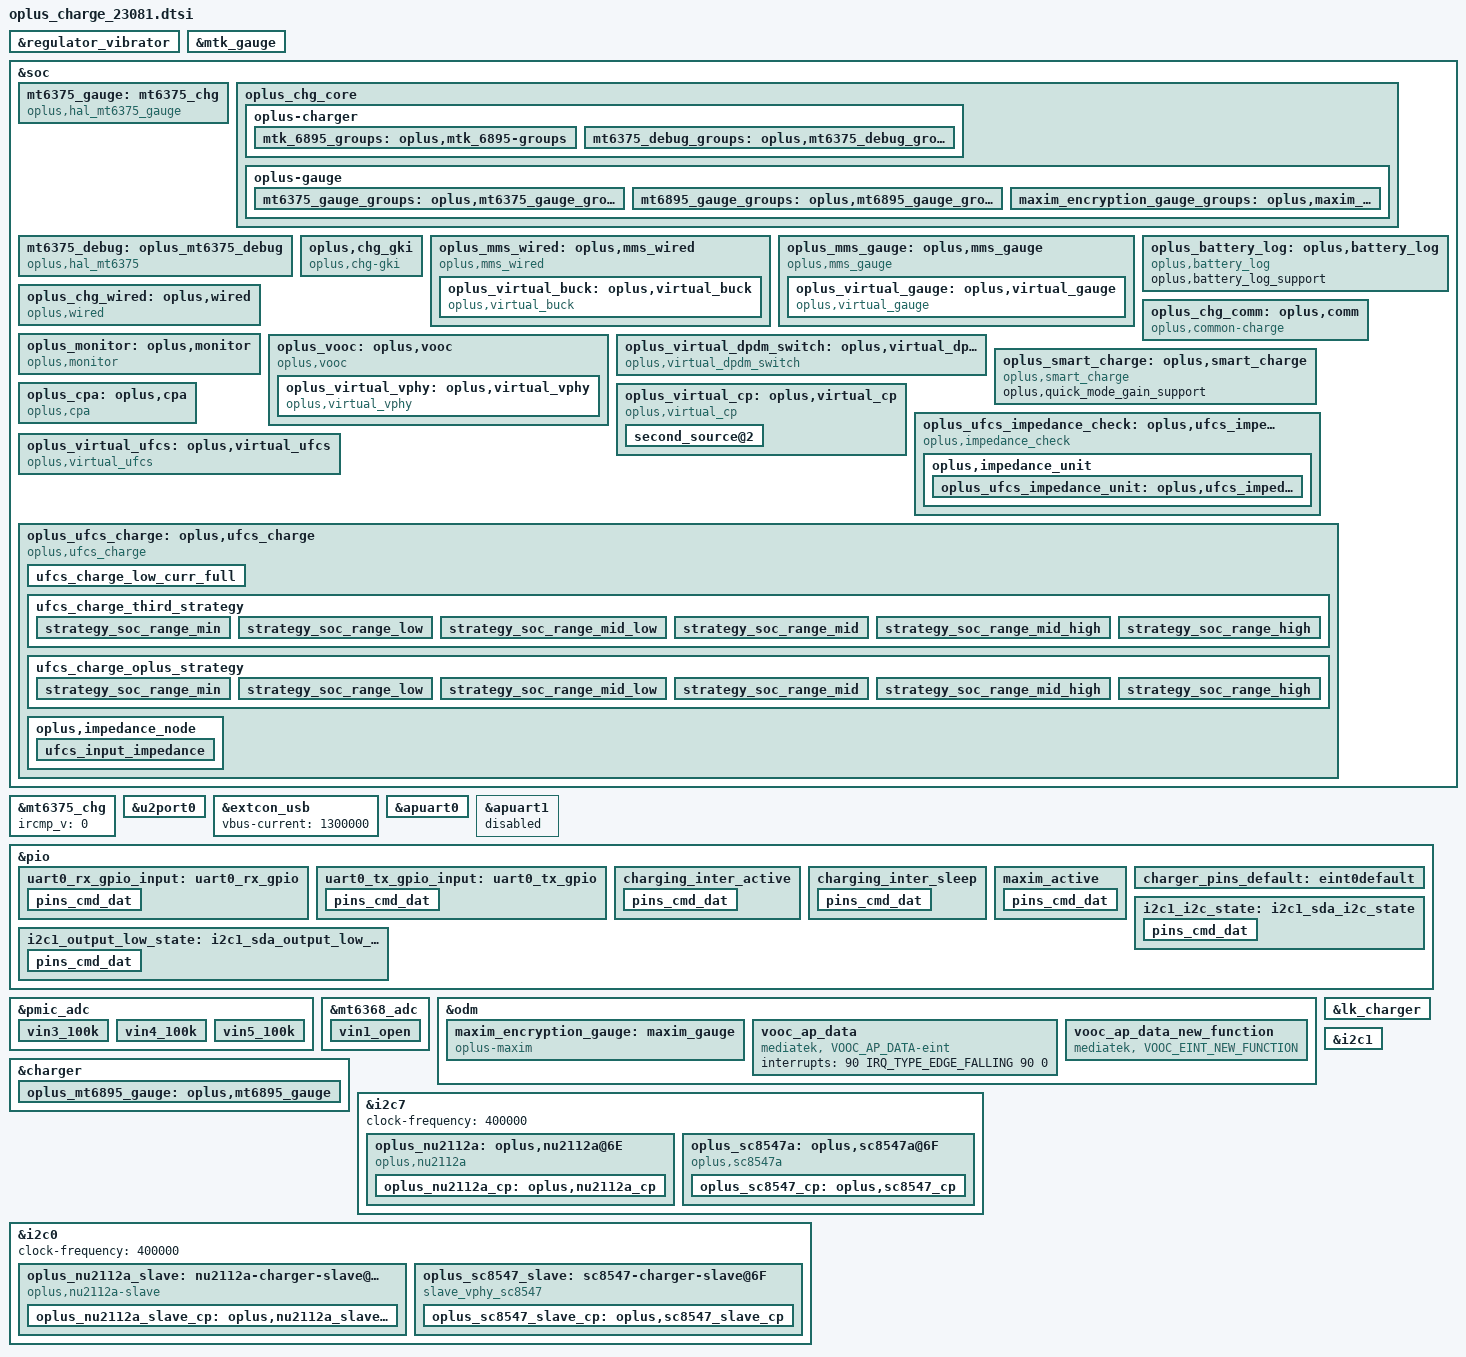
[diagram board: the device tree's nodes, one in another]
// SPDX-License-Identifier: GPL-2.0-only
/*
* Copyright (C) 2021-2020 Oplus. All rights reserved.
*/
#include <dt-bindings/iio/mt635x-auxadc.h>
#include <dt-bindings/pinctrl/mt6373-pinfunc.h>
#include <dt-bindings/pinctrl/mt65xx.h>
#include "oplus_chg.h"

/*
* ship mode gpio 119
* uart rx gpio88
* uart tx gpio89
* ntc adc need modify
*/

/* charge start */
&regulator_vibrator{
	min-volt = <3000000>;
	max-volt = <3000000>;
};

&mtk_gauge {
	status = "okay";
	charger = <&mt6375_chg>;
	FUELGAGUE_APPLY = <(1)>;
	IS_SUBBOARD_TEMP_SUPPORT = <(0)>;
	Enable_Is_Force_Full = <(1)>;
	RBAT_PULL_DOWN_R = <(24000)>;
	RBAT_PULL_UP_R = <(12000)>;
	USE_MORE_PRECISE_NTC_TABLE = <(1)>;
	R_FG_VALUE = <(1)>;
	CAR_TUNE_VALUE = <(109)>;
	AGING_FACTOR_MIN = <(93)>;
	AGING_FACTOR_DIFF = <(1)>;
	#include "mediatek/bat_setting/mt6895_23081_battery_table_ext.dtsi"
	#include "mediatek/bat_setting/mt6895_23081_battery_prop_dim2_ext.dtsi"
};

&soc {
	mt6375_gauge: mt6375_chg {
		status = "okay";
		compatible = "oplus,hal_mt6375_gauge";

		oplus,ic_type = <OPLUS_CHG_IC_GAUGE>;
		oplus,ic_index = <0>;
		oplus,batt_num = <1>;
		oplus,mtk_gauge_power_sel_support;
	};
};

&mt6375_chg {
	ircmp_v = <0>;
};

&u2port0 {
	mediatek,eye-vrt = <7>;
	mediatek,eye-term = <7>;
	mediatek,rev6 = <3>;
	mediatek,eye-vrt-host = <3>;
	mediatek,eye-term-host = <2>;
	mediatek,rev6-host = <3>;
	mediatek,discth = <0xd>;
};

&extcon_usb {
	vbus-current = <1300000>;
};

&apuart0 {
	pinctrl-names = "uart0_rx_gpio", "uart0_tx_gpio";
	pinctrl-0 = <&uart0_rx_gpio_input>;
	pinctrl-1 = <&uart0_tx_gpio_input>;
	status = "okay";
};

&apuart1 {
	status = "disabled";
};

&pio {
	uart0_rx_gpio_input: uart0_rx_gpio {
		pins_cmd_dat {
			pinmux = <PINMUX_GPIO88__FUNC_GPIO88>; /* URXD0 */
			input-enable;
			bias-disable;
		};
	};

	uart0_tx_gpio_input: uart0_tx_gpio {
		pins_cmd_dat {
			pinmux = <PINMUX_GPIO89__FUNC_GPIO89>; /* UTXD0 */
			input-enable;
			bias-disable;
		};
	};
};

&pmic_adc {
	vin3_100k {
		channel = <AUXADC_VIN3>;
		pures = <ADC_PURES_100K>;
	};
	vin4_100k {
		channel = <AUXADC_VIN4>;
		pures = <ADC_PURES_100K>;
	};
	vin5_100k {
		channel = <AUXADC_VIN5>;
		pures = <ADC_PURES_100K>;
	};
};

&mt6368_adc {
        vin1_open {
                channel = <AUXADC_VIN1>;
                pures = <ADC_PURES_OPEN>;
        };
};

&pio {
	charging_inter_active: charging_inter_active {
		pins_cmd_dat {
			pinmux = <PINMUX_GPIO10__FUNC_GPIO10>;
			input-enable;
			bias-pull-up;
			slew-rate = <0>;
		};
	};
	charging_inter_sleep: charging_inter_sleep {
		pins_cmd_dat {
			pinmux = <PINMUX_GPIO10__FUNC_GPIO10>;
			slew-rate = <0>;
		};
	};
};

&soc {
	oplus_chg_core {
		oplus,chg_framework_v2;
		oplus,smart_charging_screenoff;

		oplus-charger {
			mtk_6895_groups: oplus,mtk_6895-groups {
				functions = <
					OPLUS_IC_FUNC_INIT
					OPLUS_IC_FUNC_EXIT
					OPLUS_IC_FUNC_REG_DUMP
					OPLUS_IC_FUNC_SMT_TEST
					OPLUS_IC_FUNC_BUCK_INPUT_PRESENT
					OPLUS_IC_FUNC_BUCK_INPUT_SUSPEND
					OPLUS_IC_FUNC_BUCK_INPUT_IS_SUSPEND
					OPLUS_IC_FUNC_BUCK_OUTPUT_SUSPEND
					OPLUS_IC_FUNC_BUCK_OUTPUT_IS_SUSPEND
					OPLUS_IC_FUNC_BUCK_SET_ICL
					OPLUS_IC_FUNC_BUCK_GET_ICL
					OPLUS_IC_FUNC_BUCK_SET_FCC
					OPLUS_IC_FUNC_BUCK_SET_FV
					OPLUS_IC_FUNC_BUCK_SET_ITERM
					OPLUS_IC_FUNC_BUCK_GET_INPUT_CURR
					OPLUS_IC_FUNC_BUCK_GET_INPUT_VOL
					OPLUS_IC_FUNC_OTG_BOOST_ENABLE
					OPLUS_IC_FUNC_BUCK_GET_CC_ORIENTATION
					OPLUS_IC_FUNC_BUCK_GET_CHARGER_TYPE
					OPLUS_IC_FUNC_BUCK_RERUN_BC12
					OPLUS_IC_FUNC_BUCK_QC_DETECT_ENABLE
					OPLUS_IC_FUNC_BUCK_SET_QC_CONFIG
					OPLUS_IC_FUNC_BUCK_SET_PD_CONFIG
					OPLUS_IC_FUNC_GET_SHUTDOWN_SOC
					OPLUS_IC_FUNC_BACKUP_SOC
					OPLUS_IC_FUNC_GET_TYPEC_MODE
					OPLUS_IC_FUNC_SET_TYPEC_MODE
					OPLUS_IC_FUNC_GET_OTG_ENABLE
					OPLUS_IC_FUNC_BUCK_GET_HW_DETECT
					OPLUS_IC_FUNC_SET_USB_DISCHG_ENABLE
					OPLUS_IC_FUNC_GET_USB_DISCHG_STATUS
					OPLUS_IC_FUNC_IS_OPLUS_SVID
					OPLUS_IC_FUNC_BUCK_GET_TYPEC_STATE
					OPLUS_IC_FUNC_BUCK_GET_USB_BTB_TEMP
					OPLUS_IC_FUNC_BUCK_GET_BATT_BTB_TEMP
					OPLUS_IC_FUNC_BUCK_SHIPMODE_ENABLE
					OPLUS_IC_FUNC_BUCK_SET_AICL_POINT
					OPLUS_IC_FUNC_SET_OTG_BOOST_CURR_LIMIT
					OPLUS_IC_FUNC_GET_TYPEC_ROLE
				>;
				virqs = <
					OPLUS_IC_VIRQ_ERR
					OPLUS_IC_VIRQ_CC_DETECT
					OPLUS_IC_VIRQ_PLUGIN
					OPLUS_IC_VIRQ_CC_CHANGED
					OPLUS_IC_VIRQ_CHG_TYPE_CHANGE
					OPLUS_IC_VIRQ_OTG_ENABLE
					OPLUS_IC_VIRQ_SVID
					OPLUS_IC_VIRQ_TYPEC_STATE
				>;
			};

			mt6375_debug_groups: oplus,mt6375_debug_groups {
				functions = <
					OPLUS_IC_FUNC_INIT
					OPLUS_IC_FUNC_EXIT
				>;
				virqs = <
					OPLUS_IC_VIRQ_ERR
				>;
			};
		};

		oplus-gauge {
			mt6375_gauge_groups: oplus,mt6375_gauge_groups {
				functions = <
					OPLUS_IC_FUNC_INIT
					OPLUS_IC_FUNC_EXIT
					OPLUS_IC_FUNC_REG_DUMP
					OPLUS_IC_FUNC_SMT_TEST
					OPLUS_IC_FUNC_GAUGE_GET_BATT_VOL
					OPLUS_IC_FUNC_GAUGE_GET_BATT_MAX
					OPLUS_IC_FUNC_GAUGE_GET_BATT_MIN
					OPLUS_IC_FUNC_GAUGE_GET_BATT_CURR
					OPLUS_IC_FUNC_GAUGE_GET_BATT_TEMP
					OPLUS_IC_FUNC_GAUGE_GET_BATT_SOC
					OPLUS_IC_FUNC_GAUGE_GET_BATT_FCC
					OPLUS_IC_FUNC_GAUGE_GET_BATT_CC
					OPLUS_IC_FUNC_GAUGE_GET_BATT_RM
					OPLUS_IC_FUNC_GAUGE_GET_BATT_SOH
					OPLUS_IC_FUNC_GAUGE_GET_BATT_HMAC
					OPLUS_IC_FUNC_GAUGE_SET_BATT_FULL
					OPLUS_IC_FUNC_GAUGE_UPDATE_DOD0
					OPLUS_IC_FUNC_GAUGE_UPDATE_SOC_SMOOTH
					OPLUS_IC_FUNC_GAUGE_GET_CB_STATUS
					OPLUS_IC_FUNC_GAUGE_GET_BATT_NUM
					OPLUS_IC_FUNC_GAUGE_GET_DEVICE_TYPE
					OPLUS_IC_FUNC_GAUGE_GET_DEVICE_TYPE_FOR_VOOC
					OPLUS_IC_FUNC_GAUGE_GET_BATT_FCC
					OPLUS_IC_FUNC_GAUGE_GET_BATT_FC
					OPLUS_IC_FUNC_GAUGE_GET_BATT_QM
					OPLUS_IC_FUNC_GAUGE_GET_BATT_PD
					OPLUS_IC_FUNC_GAUGE_GET_BATT_RCU
					OPLUS_IC_FUNC_GAUGE_GET_BATT_RCF
					OPLUS_IC_FUNC_GAUGE_GET_BATT_FCU
					OPLUS_IC_FUNC_GAUGE_GET_BATT_FCF
					OPLUS_IC_FUNC_GAUGE_GET_BATT_SOU
					OPLUS_IC_FUNC_GAUGE_GET_BATT_DO0
					OPLUS_IC_FUNC_GAUGE_GET_BATT_DOE
					OPLUS_IC_FUNC_GAUGE_GET_BATT_TRM
					OPLUS_IC_FUNC_GAUGE_GET_BATT_PC
					OPLUS_IC_FUNC_GAUGE_GET_BATT_QS
					OPLUS_IC_FUNC_GAUGE_IS_SUSPEND
					OPLUS_IC_FUNC_GAUGE_GET_BCC_PARMS
					OPLUS_IC_FUNC_GAUGE_FASTCHG_UPDATE_BCC_PARMS
					OPLUS_IC_FUNC_GAUGE_GET_PREV_BCC_PARMS
					OPLUS_IC_FUNC_GAUGE_SET_BCC_PARMS
					OPLUS_IC_FUNC_GAUGE_SET_PROTECT_CHECK
					OPLUS_IC_FUNC_GAUGE_GET_AFI_UPDATE_DONE
					OPLUS_IC_FUNC_GAUGE_CHECK_RESET
					OPLUS_IC_FUNC_GAUGE_GET_DEVICE_TYPE_FOR_BCC
					OPLUS_IC_FUNC_GAUGE_GET_DOD0
					OPLUS_IC_FUNC_GAUGE_GET_DOD0_PASSED_Q
					OPLUS_IC_FUNC_GAUGE_GET_QMAX
					OPLUS_IC_FUNC_GAUGE_GET_QMAX_PASSED_Q
					OPLUS_IC_FUNC_GAUGE_SET_BATTERY_CURVE
				>;
				virqs = <
					OPLUS_IC_VIRQ_ERR
					OPLUS_IC_VIRQ_OFFLINE
					OPLUS_IC_VIRQ_RESUME
				>;
			};

			mt6895_gauge_groups: oplus,mt6895_gauge_groups {
				functions = <
					OPLUS_IC_FUNC_INIT
					OPLUS_IC_FUNC_EXIT
					OPLUS_IC_FUNC_GAUGE_GET_SUBBOARD_TEMP
				>;
				virqs = <
					OPLUS_IC_VIRQ_ERR
				>;
			};

			maxim_encryption_gauge_groups: oplus,maxim_encryption_gauge_groups {
				functions = <
					OPLUS_IC_FUNC_INIT
					OPLUS_IC_FUNC_EXIT
					OPLUS_IC_FUNC_GAUGE_GET_BATT_AUTH
				>;
				virqs = <
					OPLUS_IC_VIRQ_ERR
				>;
			};
		};
	};
};

&soc {
	mt6375_debug: oplus_mt6375_debug {
		status = "okay";
		compatible = "oplus,hal_mt6375";

		oplus,tcpc_name = "type_c_port0";

		oplus,ic_type = <OPLUS_CHG_IC_BUCK>;
		oplus,ic_index = <1>;
	};
};

&odm {
	maxim_encryption_gauge: maxim_gauge {
		status = "okay";
		compatible = "oplus-maxim";
		support_encryption_in_lk;
		pinctrl-names = "maxim_active";
		pinctrl-0 = <&maxim_active>;
		data-gpio = <&pio 104 0x00>;
		gpio-addr-set-out = <0x10005034>;
		gpio-addr-set-in = <0x10005038>;
		gpio-addr-level_high = <0x10005134>;
		gpio-addr-level_low = <0x10005138>;
		gpio-addr-data-in = <0x10005230>;
		gpio-addr-offset = <0x8>;

		oplus,batt_info = /bits/ 8 <0x36 0x31 0x31 0x33 0x30 0x33 0x30 0x30 0x30 0x30 0x36 0x35>;

		oplus,ic_type = <OPLUS_CHG_IC_GAUGE>;
		oplus,ic_index = <2>;
	};
};

&pio {
	maxim_active: maxim_active {
		pins_cmd_dat {
			pinmux = <PINMUX_GPIO104__FUNC_GPIO104>;
			//slew-rate = <1>;
			drive-strength = <6>;
			bias-pull-up;
		};
	};
};

&soc {
	oplus,chg_gki {
		compatible = "oplus,chg-gki";
	};
};

&charger {
	io-channels = <&mt6368_adc (ADC_PURES_OPEN_MASK | AUXADC_VIN1)>, <&pmic_adc AUXADC_VIN5>, <&pmic_adc AUXADC_VIN6>, <&mt6368_adc (ADC_PURES_OPEN_MASK | AUXADC_VIN2)>;
	io-channel-names = "auxadc1-ntc_sub_bat_tem", "auxadc5-chargeric_temp", "auxadc5_batt_btb_temp", "auxadc6_usb_btb_temp";

	pinctrl-names = "default";
	pinctrl-0 = <&charger_pins_default>;
	oplus,support_ntc_01c_precision;
	oplus,support_subboard_ntc;
	max_charger_voltage = <15000000>;
	/* ntc_resistance:100k internal_pull_up:100k voltage:1.84v */
	oplus,ntc_temp_volt_1840mv;

	oplus,ic_type = <OPLUS_CHG_IC_BUCK>;
	oplus,ic_index = <0>;

	oplus_mt6895_gauge: oplus,mt6895_gauge {
		oplus,ic_type = <OPLUS_CHG_IC_GAUGE>;
		oplus,ic_index = <1>;
	};
};

&odm {
	vooc_ap_data:vooc_ap_data {
		compatible = "mediatek, VOOC_AP_DATA-eint";
		interrupts = <90 IRQ_TYPE_EDGE_FALLING 90 0>;
	};
	vooc_ap_data_new_function:vooc_ap_data_new_function {
		compatible = "mediatek, VOOC_EINT_NEW_FUNCTION";
	};
};


&i2c7 {
	status = "okay";
	clock-frequency = <400000>;
	oplus_nu2112a: oplus,nu2112a@6E {
		status = "okay";
		compatible = "oplus,nu2112a";
		reg = <0x6E>;

		ocp_reg = <0x2E>;
		ovp_reg = <0x70>;
		#include "mediatek/oplus_charge_23081_charging_curve.dtsi"

		oplus_nu2112a_cp: oplus,nu2112a_cp {
			oplus,ic_type = <OPLUS_CHG_IC_CP>;
			oplus,ic_index = <0>;
		};
	};

	oplus_sc8547a: oplus,sc8547a@6F {
		status = "okay";
		compatible = "oplus,sc8547a";
		reg = <0x6F>;

		ocp_reg = <0xd>;
		ovp_reg = <0x36>;
		#include "mediatek/oplus_charge_23081_charging_curve.dtsi"

		oplus_sc8547_cp: oplus,sc8547_cp {
			oplus,ic_type = <OPLUS_CHG_IC_CP>;
			oplus,ic_index = <0>;
		};
	};
};

&i2c0 {
	status = "okay";
	clock-frequency = <400000>;
	oplus_nu2112a_slave: nu2112a-charger-slave@6E{
		status = "okay";
		compatible = "oplus,nu2112a-slave";
		reg = <0x6E>;

		ocp_reg = <0x2E>;
		ovp_reg = <0x70>;
		oplus_nu2112a_slave_cp: oplus,nu2112a_slave_cp {
			oplus,ic_type = <OPLUS_CHG_IC_CP>;
			oplus,ic_index = <1>;
		};
	};

	oplus_sc8547_slave: sc8547-charger-slave@6F{
		status = "okay";
		compatible = "slave_vphy_sc8547";
		reg = <0x6F>;

		ocp_reg = <0xd>;
		ovp_reg = <0x36>;
		oplus_sc8547_slave_cp: oplus,sc8547_slave_cp {
			oplus,ic_type = <OPLUS_CHG_IC_CP>;
			oplus,ic_index = <1>;
		};
	};
};

&pio {
	charger_pins_default: eint0default {
	};
};

&lk_charger {
	en_vol_ctrl_vibrate = <3200>;
	support_tuv_authentication;
	support_hot_enter_kpoc;
	charger_no_wiress;
	support_battery_type = <2>;
	support_maxim_battery_authentication;
	data-gpio = <104>;
	//cpu-id = <7>;
	//key-id = <1>;

	oplus,batt_info = /bits/ 8 <0x36 0x31 0x31 0x33 0x30 0x33 0x30 0x30 0x30 0x30 0x36 0x35>;

	sub_board_temp_support;
	over_high_temp_thr = <60>;
	sub_board_adc_channel = <18>;		/* AUXADC_CHAN_VIN1 in LK, Use the MT6368 PMIC */
	sub_board_adc_pmic = <1>;		/* Vivien use the MT6368 Pmic, in lk2 it's name is "second_pmic_sdmadc" */
	sub_board_adc_pull_up_voltage = <1840>;
	sub_board_adc_pures = <3>;	/* Vivien config as SDMADC_OPEN */

	support_sdp_screenoff;
	support_quickboot_charge;
	led_brightness = <102>;
	max_charger_voltage = <15000000>;
	boot_battery_voltage = <3350000>;
	usb_charger_current = <500000>;
	ac_charger_current = <2050000>;
	ac_charger_input_current = <1500000>;
	non_std_ac_charger_current = <750000>;
	charging_host_charger_current = <1500000>;
	ta_ac_charger_current = <1500000>;
	pd_charger_current = <500000>;
};

&i2c1 {
	pinctrl-names = "i2c-state", "output-low-state";
	pinctrl-0 = <&i2c1_i2c_state>;
	pinctrl-1 = <&i2c1_output_low_state>;
};

&pio {
	i2c1_i2c_state: i2c1_sda_i2c_state {
		pins_cmd_dat {
			pinmux = <PINMUX_GPIO9__FUNC_SDA1>; /* GAUGE_SDA */
			bias-pull-up;
		};
	};
	i2c1_output_low_state: i2c1_sda_output_low_state {
		pins_cmd_dat {
			pinmux = <PINMUX_GPIO9__FUNC_GPIO9>;
			output-low;
		};
	};
};

&soc {
	oplus_mms_wired: oplus,mms_wired {
		compatible = "oplus,mms_wired";
		oplus,buck_ic = <&oplus_virtual_buck>;
		oplus,voocphy_ic = <&oplus_virtual_vphy>;
		oplus,adc_info_name = "100k_1840mv";
		oplus_spec,usbtemp_batttemp_gap = <12>;

		/* support for V2.0 usbtemp protect. */
		oplus,support_usbtemp_protect_v2;
		oplus_spec,usbtemp_batt_temp_low = <50>;
		oplus_spec,usbtemp_batt_temp_high = <50>;
		oplus_spec,usbtemp_batt_temp_over_hot = <60>;
		oplus_spec,usbtemp_ntc_temp_low = <57>;
		oplus_spec,usbtemp_ntc_temp_high = <69>;
		oplus_spec,usbtemp_temp_gap_low_with_batt_temp = <7>;
		oplus_spec,usbtemp_temp_gap_with_batt_temp_in_over_hot = <15>;
		oplus_spec,usbtemp_temp_gap_high_with_batt_temp = <12>;
		oplus_spec,usbtemp_temp_gap_low_without_batt_temp = <12>;
		oplus_spec,usbtemp_temp_gap_high_without_batt_temp = <24>;
		oplus_spec.usbtemp_rise_fast_temp_low = <3>;
		oplus_spec.usbtemp_rise_fast_temp_high = <3>;
		oplus_spec.usbtemp_rise_fast_temp_count_low = <30>;
		oplus_spec.usbtemp_rise_fast_temp_count_high = <20>;
		oplus_spec,usbtemp_cool_down_ntc_low = <54>;
		oplus_spec,usbtemp_cool_down_ntc_high = <65>;
		oplus_spec,usbtemp_cool_down_gap_low = <12>;
		oplus_spec,usbtemp_cool_down_gap_high = <20>;
		oplus_spec,usbtemp_cool_down_recover_ntc_low = <48>;
		oplus_spec,usbtemp_cool_down_recover_ntc_high = <60>;
		oplus_spec,usbtemp_cool_down_recover_gap_low = <6>;
		oplus_spec,usbtemp_cool_down_recover_gap_high = <15>;

		oplus_virtual_buck: oplus,virtual_buck {
			compatible = "oplus,virtual_buck";
			oplus,buck_ic = <&charger &mt6375_debug>;
			oplus,buck_ic_index = <0 1>;
			oplus,buck_ic_current_ratio = <100 0>;
			oplus,buck_ic_connect = <OPLUS_CHG_IC_CONNECT_PARALLEL>;
			oplus,main_charger = <0>;
			oplus,buck_ic_func_group = <&mtk_6895_groups &mt6375_debug_groups>;

			oplus,ic_type = <OPLUS_CHG_IC_VIRTUAL_BUCK>;
			oplus,ic_index = <0>;

			io-channels = <&pmic_adc AUXADC_VIN3>, <&pmic_adc AUXADC_VIN4>;
			io-channel-names = "usb_temp_adc_l", "usb_temp_adc_r";

			oplus,uart_tx-gpio = <&pio 89 0x00>;
			oplus,uart_rx-gpio = <&pio 88 0x00>;
		};
	};

	oplus_mms_gauge: oplus,mms_gauge {
		compatible = "oplus,mms_gauge";
		oplus,gauge_ic = <&oplus_virtual_gauge>;
		oplus,voocphy_ic = <&oplus_virtual_vphy>;
		oplus,topic-update-interval = <10000>;
		oplus,support_subboard_ntc;

		oplus_virtual_gauge: oplus,virtual_gauge {
			compatible = "oplus,virtual_gauge";
			oplus,gauge_ic = <&mt6375_gauge &oplus_mt6895_gauge &maxim_encryption_gauge>;
			oplus,gauge_ic_index = <0 1 2>;
			oplus,gauge_ic_func_group = <&mt6375_gauge_groups &mt6895_gauge_groups &maxim_encryption_gauge_groups>;
			oplus,batt_capacity_mah = <5000>;
			oplus,ic_type = <OPLUS_CHG_IC_VIRTUAL_GAUGE>;
			oplus,ic_index = <0>;
		};
	};
};

&soc {
	oplus_battery_log: oplus,battery_log {
		compatible = "oplus,battery_log";

		oplus,battery_log_support;
	};

	oplus_chg_wired: oplus,wired {
		compatible = "oplus,wired";

		oplus,vooc-support;

		oplus_spec,vbatt_pdqc_to_5v_thr = <4500>;
		oplus_spec,vbatt_pdqc_to_9v_thr = <4500>;
		oplus_spec,pd-iclmax-ma = <1500>;
		oplus_spec,qc-iclmax-ma = <1500>;
		oplus_spec,non-standard-ibatmax-ma = <500>;
		oplus_spec,input-power-mw = <
			2500		/* OPLUS_WIRED_CHG_MODE_UNKNOWN */
			2500		/* OPLUS_WIRED_CHG_MODE_SDP */
			7500		/* OPLUS_WIRED_CHG_MODE_CDP */
			10000		/* OPLUS_WIRED_CHG_MODE_DCP */
			18000		/* OPLUS_WIRED_CHG_MODE_VOOC */
			18000		/* OPLUS_WIRED_CHG_MODE_QC */
			18000		/* OPLUS_WIRED_CHG_MODE_PD */
		>;
		oplus_spec,led_on-fccmax-ma = <0 1220 3300 3300 3300 3300 1000 0>;
		oplus_spec,fccmax-ma-lv = <
			0 555  1100 1100 1100 1100 1100 0	/* OPLUS_WIRED_CHG_MODE_UNKNOWN */
			0 600  600  600  600  600  600  0	/* OPLUS_WIRED_CHG_MODE_SDP */
			0 1220 1600 1600 1600 1600 1600 0	/* OPLUS_WIRED_CHG_MODE_CDP */
			0 1220 2200 2200 2200 2200 2200 0	/* OPLUS_WIRED_CHG_MODE_DCP */
			0 555  1800 1800 1800 1800 1221 0	/* OPLUS_WIRED_CHG_MODE_VOOC */
			0 1220 3300 3300 3300 3300 2684 0	/* OPLUS_WIRED_CHG_MODE_QC */
			0 1220 3300 3300 3300 3300 2684 0	/* OPLUS_WIRED_CHG_MODE_PD */
		>;
		oplus_spec,fccmax-ma-hv = <
			0 555  1100 1100 1100 1100 1100 0	/* OPLUS_WIRED_CHG_MODE_UNKNOWN */
			0 600  600  600  600  600  600  0	/* OPLUS_WIRED_CHG_MODE_SDP */
			0 1220 1600 1600 1600 1600 1600 0	/* OPLUS_WIRED_CHG_MODE_CDP */
			0 1220 2200 2200 2200 2200 2200 0	/* OPLUS_WIRED_CHG_MODE_DCP */
			0 555  1665 1800 1800 1800 1221 0	/* OPLUS_WIRED_CHG_MODE_VOOC */
			0 1220 3300 3300 3300 3300 2684 0	/* OPLUS_WIRED_CHG_MODE_QC */
			0 1220 3300 3300 3300 3300 2684 0	/* OPLUS_WIRED_CHG_MODE_PD */
		>;

		oplus_spec,cool_down_pdqc_vol_mv = <9000 9000 9000>;
		oplus_spec,cool_down_pdqc_curr_ma = <1200 1500 2000>;
		oplus_spec,cool_down_vooc_curr_ma = <1200 1500 2000 2500 3000 3600>;
		oplus_spec,cool_down_normal_curr_ma = <1200 1500 2000>;

		oplus_spec,vbus_ov_thr_mv = <11000 11000>;
		oplus_spec,vbus_uv_thr_mv = <4300 4300>;

		/* first data is strategy used temp type */
		oplus,vooc_strategy_name = "cgcl";
		oplus,vooc_strategy_data = <OPLUS_STRATEGY_USE_BATT_TEMP
					    0   350 3600 1 0
					    330 370 3200 2 0
					    350 440 2200 2 1>;
	};

	oplus_chg_comm: oplus,comm {
		compatible = "oplus,common-charge";
		oplus_spec,batt-them-thr = <(-100) 0 50 120 160 450 530>;
		oplus_spec,iterm-ma = <254>;
		oplus_spec,removed_bat_decidegc = <390>; /*-39 degree*/
		oplus_spec,fv-mv = <0 4470 4470 4470 4470 4470 4130 4130>;
		oplus_spec,sw-fv-mv = <0 4420 4420 4420 4420 4420 4080 4080>;
		oplus_spec,hw-fv-inc-mv = <0 18 18 18 18 18 18 0>;
		oplus_spec,sw-over-fv-mv = <0 4480 4480 4480 4480 4480 4140 4140>;
		oplus_spec,sw-over-fv-dec-mv = <8>;
		oplus_spec,non-standard-sw-fv-mv = <3930>;
		oplus_spec,non-standard-fv-mv = <3980>;
		oplus_spec,non-standard-hw-fv-inc-mv = <18>;
		oplus_spec,non-standard-sw-over-fv-mv = <3990>;
		oplus_spec,non-standard-vbatdet-mv = <3600>;
		oplus_spec,wired-vbatdet-mv = <0 4170 4270 4370 4370 4370 4030 0>;
		oplus_spec,wls-vbatdet-mv = <0 3675 4235 4370 4370 4370 4030 0>;
		oplus_spec,fcc-gear-thr-mv = <4180>;
		oplus_spec,vbatt-ov-thr-mv = <4600>;

		oplus_spec,full_pre_ffc_judge;
		oplus_spec,full-pre-ffc-mv = <4490>;
		oplus_spec,ffc-temp-thr = <120 350 430>;
		oplus_spec,wired-ffc-step-max = <2>;
		oplus_spec,wired-ffc-fv-mv = <4600 4600>;

		oplus_spec,wired-ffc-fv-cutoff-mv = <4525 4525 4525 4525>;
		oplus_spec,wired-ffc-fcc-ma = <1750 1900
					       1650 1800>;
		oplus_spec,wired-ffc-fcc-cutoff-ma = <1550 1700
						      1550 1700>;
		/* 2s battery */
		oplus_spec,wls-ffc-step-max = <2>;
		oplus_spec,wls-ffc-fv-mv = <4500 4500>;
		oplus_spec,wls-ffc-fv-cutoff-mv = <4445 4435>;
		oplus_spec,wls-ffc-icl-ma = <800 800
					     550  550>;
		oplus_spec,wls-ffc-fcc-ma = <550 550
					     350 350>;
		oplus_spec,wls-ffc-fcc-cutoff-ma = <400 400
						    200 200>;
		oplus_spec,vbat_uv_thr_mv = <3300>;
		oplus_spec,vbat_charging_uv_thr_mv = <3200>;

		/*If use subboard NTC as battery temp, config it as 20, otherwise 0 */
		oplus_spec,tbatt_power_off_cali_temp = <0>;
		oplus_spec,poweroff_high_batt_temp = <720>;
		oplus_spec,poweroff_emergency_batt_temp = <770>;
		oplus,vooc_show_ui_soc_decimal;
		oplus,ui_soc_decimal_speedmin = <20>;
		oplus,gauge_stuck_jump_support;
		oplus,gauge_stuck_threshold = <15>;
		oplus,gauge_stuck_time = <50>;
	};

	oplus_monitor: oplus,monitor {
		compatible = "oplus,monitor";
		oplus,topic-update-interval = <60000>;

		track,fast_chg_break_t_thd = <1000>;
		track,general_chg_break_t_thd = <200>;
		track,voocphy_type = <2>;
		track,wired_max_power = <80000>;
		track,wired_fast_chg_scheme = <2>;
	};

	oplus_vooc: oplus,vooc {
		compatible = "oplus,vooc";
		oplus,vooc_ic = <&oplus_virtual_vphy>;

		oplus_spec,vooc_soc_range = <50 75 85>;
		oplus_spec,vooc_temp_range = <50 120 180 350 450>;

		oplus,vooc_data_width = <7>;
		oplus,vooc_curr_max = <CP_CURR_LIMIT_7BIT_15_0A>; /* 80W: 11V 7.3A(IBUS *2) */
		oplus,vooc_power_max_w = <80>;
		oplus,vooc_project = <7>;
		oplus,vooc_curr_table_type = <VOOC_CP_CURR_TABLE>;
		oplus,voocphy_support = <3>; /* AP_DUAL_CP_VOOCPHY */
		oplus,support_fake_vooc_check;
		oplus,subboard_ntc_abnormal_current = <4000>;

		oplus,abnormal_adapter_current = <CP_CURR_LIMIT_7BIT_15_0A CP_CURR_LIMIT_7BIT_15_0A
						CP_CURR_LIMIT_7BIT_12_6A CP_CURR_LIMIT_7BIT_12_6A
						CP_CURR_LIMIT_7BIT_10_0A CP_CURR_LIMIT_7BIT_10_0A
						CP_CURR_LIMIT_7BIT_8_0A CP_CURR_LIMIT_7BIT_8_0A
						CP_CURR_LIMIT_7BIT_6_0A CP_CURR_LIMIT_7BIT_6_0A
						CP_CURR_LIMIT_7BIT_4_0A CP_CURR_LIMIT_7BIT_4_0A>;

		/* first data is strategy used temp type */
		oplus,general_strategy_name = "cgcl";
		oplus,general_strategy_data = < OPLUS_STRATEGY_USE_SHELL_TEMP
						0   385 CP_CURR_LIMIT_7BIT_15_0A 1 0
						375 395 CP_CURR_LIMIT_7BIT_12_6A 2 0
						385 420 CP_CURR_LIMIT_7BIT_8_0A 3 1
						410 440 CP_CURR_LIMIT_7BIT_6_0A 3 2 >;

		oplus_virtual_vphy: oplus,virtual_vphy {
			compatible = "oplus,virtual_vphy";
			oplus,vphy_ic = <&oplus_nu2112a &oplus_sc8547a>;
			oplus,dpdm_switch_ic = <&oplus_virtual_dpdm_switch>;

			oplus,ic_type = <OPLUS_CHG_IC_VIRTUAL_VPHY>;
			oplus,ic_index = <0>;

		};
	};
	oplus_virtual_dpdm_switch: oplus,virtual_dpdm_switch {
		compatible = "oplus,virtual_dpdm_switch";

		oplus,ic_type = <OPLUS_CHG_IC_MISC>;
		oplus,ic_index = <0>;

		oplus,use_audio_switch;
	};
	oplus_smart_charge: oplus,smart_charge {
		compatible = "oplus,smart_charge";
		oplus,quick_mode_gain_support;
	};
};

&soc {
	oplus_virtual_cp: oplus,virtual_cp {
		compatible = "oplus,virtual_cp";

		oplus,ic_type = <OPLUS_CHG_IC_VIRTUAL_CP>;
		oplus,ic_index = <0>;

		oplus,cp_ic = <&oplus_nu2112a_cp &oplus_nu2112a_slave_cp>;
		oplus,input_curr_max_ma = <3000 0>;

		oplus,cp_ic_connect = <OPLUS_CHG_IC_CONNECT_PARALLEL>;
		oplus,main_cp = <0>;

		oplus,reg_proc_node;

		second_source@2 {
			oplus,cp_ic = <&oplus_sc8547_cp &oplus_sc8547_slave_cp>;
			oplus,input_curr_max_ma = <3000 0>;
		};
	};
};

&soc {
	oplus_ufcs_impedance_check: oplus,ufcs_impedance_check {
		compatible = "oplus,impedance_check";

		oplus,impedance_unit {
			oplus_ufcs_impedance_unit: oplus,ufcs_impedance_unit {
				uint_name = "ufcs";
				default_curr_ma = <3000>;
				impedance_node = <&ufcs_input_impedance>;
			};
		};
	};
};

//for ufcs config

&soc {
	oplus_cpa: oplus,cpa {
		compatible = "oplus,cpa";
		oplus,protocol_list = <CHG_PROTOCOL_UFCS 33
				       CHG_PROTOCOL_PD 18
				       CHG_PROTOCOL_VOOC 80
				       CHG_PROTOCOL_QC 18>;
		oplus,default_protocol_list = <CHG_PROTOCOL_UFCS
					       CHG_PROTOCOL_PD
					       CHG_PROTOCOL_VOOC>;
	};

	oplus_virtual_ufcs: oplus,virtual_ufcs {
		compatible = "oplus,virtual_ufcs";

		oplus,ic_type = <OPLUS_CHG_IC_VIRTUAL_UFCS>;
		oplus,ic_index = <0>;
	};

	oplus_ufcs_charge: oplus,ufcs_charge {
		compatible = "oplus,ufcs_charge";
		oplus,ufcs_ic = <&oplus_virtual_ufcs>;
		oplus,cp_ic = <&oplus_virtual_cp>;
		oplus,dpdm_switch_ic = <&oplus_virtual_dpdm_switch>;

		oplus,impedance_unit = <&oplus_ufcs_impedance_unit>;

		oplus,target_vbus_mv = <11000>;
		oplus,curr_max_ma = <3000>;
		oplus,high_imp_compensation_setting_mv = <100>;

		oplus,curr_table_type = <UFCS_CURR_CP_TABLE>;

		oplus,ufcs_warm_allow_vol = <4000>;
		oplus,ufcs_warm_allow_soc = <50>;
		oplus,ufcs_strategy_normal_current = <3000>;
		oplus,ufcs_over_high_or_low_current = <3000>;
		oplus,ufcs_timeout_third = <10800>;
		oplus,ufcs_timeout_oplus = <10800>;
		oplus,ufcs_ibat_over_third = <7000>;
		oplus,ufcs_ibat_over_oplus = <7000>;
		oplus,ufcs_full_cool_sw_vbat = <4470>;
		oplus,ufcs_full_normal_sw_vbat = <4520>;
		oplus,ufcs_full_normal_hw_vbat = <4530>;
		oplus,ufcs_full_ffc_vbat = <4520>;
		oplus,ufcs_full_warm_vbat = <4130>;
		oplus,ufcs_full_cool_sw_vbat_third = <4470>;
		oplus,ufcs_full_normal_sw_vbat_third= <4470>;
		oplus,ufcs_full_normal_hw_vbat_third = <4480>;
		oplus,ufcs_current_change_timeout = <100>;
		oplus,ufcs_strategy_batt_high_temp = <410 420 430 400 410 420>;
		oplus,ufcs_strategy_high_current = <3000 2000 2000 3000 3000 3000>;
		oplus,ufcs_charge_strategy_soc = <0 20 35 50 75 85 95>;
		oplus,ufcs_charge_strategy_temp = <0 50 120 200 350 440 530>;
		oplus,ufcs_low_curr_full_strategy_temp = <0 200 350 440>;

		ufcs_charge_low_curr_full {
			strategy_temp_little_cool = 	<1550 4490 0
							 1450 4485 0
							 1350 4470 0
							 1250 4460 0
							 1150 4450 1>;
			strategy_temp_normal_low =	<1550 4490 0
							 1450 4485 0
							 1350 4470 0
							 1250 4460 0
							 1150 4450 1>;
			strategy_temp_normal_high = 	<1750 4490 0
							 1650 4485 0
							 1550 4470 0
							 1450 4460 0
							 1350 4450 1>;
		};


		ufcs_charge_third_strategy {
			oplus,temp_type = <OPLUS_STRATEGY_USE_SHELL_TEMP>;
			oplus,soc_range = <0 20 35 50 75 85 95>;
			oplus,temp_range = <0 50 120 200 350 440 530>;

			strategy_soc_range_min {
				strategy_temp_little_cold =	<11000 4150 2750 0 0
								11000 4460 2750 0 0
								11000 4460 2500 0 0
								11000 4460 2000 0 0
								11000 4460 1800 0 0
								11000 4460 1500 0 0
								11000 4470 1000 1 0>;
				strategy_temp_cool =		<11000 4150 3000 0 0
								11000 4460 2800 0 0
								11000 4460 2500 0 0
								11000 4460 2000 0 0
								11000 4460 1800 0 0
								11000 4460 1500 0 0
								11000 4470 1000 1 0>;
				strategy_temp_little_cool =	<11000 4150 3000 0 0
								11000 4460 2800 0 0
								11000 4460 2500 0 0
								11000 4460 2000 0 0
								11000 4460 1800 0 0
								11000 4460 1500 0 0
								11000 4470 1000 1 0>;
				strategy_temp_normal_low =	<11000 4460 3000 0 0
								11000 4460 2500 0 0
								11000 4460 2000 0 0
								11000 4460 1500 0 0
								11000 4470 1000 1 0>;
				strategy_temp_normal_high =	<11000 4460 3000 0 0
								11000 4460 2500 0 0
								11000 4460 2000 0 0
								11000 4460 1500 0 0
								11000 4470 1000 1 0>;
				strategy_temp_warm =		<11000 4120 1300 0 0
								11000 4130 1000 1 0>;
			};
			strategy_soc_range_low {
				strategy_temp_little_cold =	<11000 4150 2750 0 0
								11000 4460 2750 0 0
								11000 4460 2500 0 0
								11000 4460 2000 0 0
								11000 4460 1800 0 0
								11000 4460 1500 0 0
								11000 4470 1000 1 0>;
				strategy_temp_cool =		<11000 4150 3000 0 0
								11000 4460 2800 0 0
								11000 4460 2500 0 0
								11000 4460 2000 0 0
								11000 4460 1800 0 0
								11000 4460 1500 0 0
								11000 4470 1000 1 0>;
				strategy_temp_little_cool =	<11000 4150 3000 0 0
								11000 4460 2800 0 0
								11000 4460 2500 0 0
								11000 4460 2000 0 0
								11000 4460 1800 0 0
								11000 4460 1500 0 0
								11000 4470 1000 1 0>;
				strategy_temp_normal_low =	<11000 4460 3000 0 0
								11000 4460 2500 0 0
								11000 4460 2000 0 0
								11000 4460 1500 0 0
								11000 4470 1000 1 0>;
				strategy_temp_normal_high =	<11000 4460 3000 0 0
								11000 4460 2500 0 0
								11000 4460 2000 0 0
								11000 4460 1500 0 0
								11000 4470 1000 1 0>;
				strategy_temp_warm =		<11000 4120 1300 0 0
								11000 4130 1000 1 0>;
			};
			strategy_soc_range_mid_low {
				strategy_temp_little_cold =	<11000 4460 2000 0 0
								11000 4460 1800 0 0
								11000 4460 1500 0 0
								11000 4470 1000 1 0>;
				strategy_temp_cool =		<11000 4460 2500 0 0
								11000 4460 2000 0 0
								11000 4460 1800 0 0
								11000 4460 1500 0 0
								11000 4470 1000 1 0>;
				strategy_temp_little_cool =	<11000 4150 3000 0 0
								11000 4460 2800 0 0
								11000 4460 2500 0 0
								11000 4460 2000 0 0
								11000 4460 1800 0 0
								11000 4460 1500 0 0
								11000 4470 1000 1 0>;
				strategy_temp_normal_low =	<11000 4460 3000 0 0
								11000 4460 2500 0 0
								11000 4460 2000 0 0
								11000 4460 1500 0 0
								11000 4470 1000 1 0>;
				strategy_temp_normal_high =	<11000 4460 3000 0 0
								11000 4460 2500 0 0
								11000 4460 2000 0 0
								11000 4460 1500 0 0
								11000 4470 1000 1 0>;
				strategy_temp_warm =		<11000 4120 1300 0 0
								11000 4130 1000 1 0>;
			};
			strategy_soc_range_mid {
				strategy_temp_little_cold =	<11000 4460 1500 0 0
								11000 4470 1000 1 0>;
				strategy_temp_cool =		<11000 4460 1500 0 0
								11000 4470 1000 1 0>;
				strategy_temp_little_cool =	<11000 4460 2000 0 0
								11000 4460 1800 0 0
								11000 4460 1500 0 0
								11000 4470 1000 1 0>;
				strategy_temp_normal_low =	<11000 4460 2000 0 0
								11000 4460 1500 0 0
								11000 4470 1000 1 0>;
				strategy_temp_normal_high =	<11000 4460 2500 0 0
								11000 4460 2000 0 0
								11000 4460 1500 0 0
								11000 4470 1000 1 0>;
				strategy_temp_warm =		<11000 4130 1000 1 0>;
			};
			strategy_soc_range_mid_high {
				strategy_temp_little_cold =	<11000 4470 1000 1 0>;
				strategy_temp_cool =		<11000 4470 1000 1 0>;
				strategy_temp_little_cool =	<11000 4460 1500 0 0
								11000 4470 1000 1 0>;
				strategy_temp_normal_low =	<11000 4460 1500 0 0
								11000 4470 1000 1 0>;
				strategy_temp_normal_high =	<11000 4460 1500 0 0
								11000 4470 1000 1 0>;
				strategy_temp_warm =		<11000 4130 1000 1 0>;
			};
			strategy_soc_range_high {
				strategy_temp_little_cold =	<11000 4470 1000 1 0>;
				strategy_temp_cool =		<11000 4470 1000 1 0>;
				strategy_temp_little_cool =	<11000 4470 1000 1 0>;
				strategy_temp_normal_low =	<11000 4470 1000 1 0>;
				strategy_temp_normal_high =	<11000 4470 1000 1 0>;
				strategy_temp_warm =		<11000 4130 1000 1 0>;
			};
		};

		ufcs_charge_oplus_strategy {
			oplus,temp_type = <OPLUS_STRATEGY_USE_SHELL_TEMP>;
			oplus,soc_range = <0 20 35 50 75 85 95>;
			oplus,temp_range = <0 50 120 200 350 440 530>;

			strategy_soc_range_min {
				strategy_temp_little_cold =	<11000 4150 2750 0 0
								11000 4460 2750 0 0
								11000 4460 2500 0 0
								11000 4460 2000 0 0
								11000 4460 1800 0 0
								11000 4460 1500 0 0
								11000 4470 1000 1 0>;
				strategy_temp_cool =		<11000 4150 3000 0 0
								11000 4460 2800 0 0
								11000 4460 2500 0 0
								11000 4460 2000 0 0
								11000 4460 1800 0 0
								11000 4460 1500 0 0
								11000 4470 1000 1 0>;
				strategy_temp_little_cool =	<11000 4150 3000 0 0
								11000 4480 2800 0 0
								11000 4480 2500 0 0
								11000 4480 2000 0 0
								11000 4520 1800 0 0
								11000 4520 1500 0 0
								11000 4530 1000 1 0>;
				strategy_temp_normal_low =	<11000 4520 3000 0 0
								11000 4520 2500 0 0
								11000 4520 2000 0 0
								11000 4520 1500 0 0
								11000 4530 1000 1 0>;
				strategy_temp_normal_high =	<11000 4520 3000 0 0
								11000 4520 2500 0 0
								11000 4520 2000 0 0
								11000 4520 1500 0 0
								11000 4530 1000 1 0>;
				strategy_temp_warm =		<11000 4120 1300 0 0
								11000 4130 1000 1 0>;
			};
			strategy_soc_range_low {
				strategy_temp_little_cold =	<11000 4150 2750 0 0
								11000 4460 2750 0 0
								11000 4460 2500 0 0
								11000 4460 2000 0 0
								11000 4460 1800 0 0
								11000 4460 1500 0 0
								11000 4470 1000 1 0>;
				strategy_temp_cool =		<11000 4150 3000 0 0
								11000 4460 2800 0 0
								11000 4460 2500 0 0
								11000 4460 2000 0 0
								11000 4460 1800 0 0
								11000 4460 1500 0 0
								11000 4470 1000 1 0>;
				strategy_temp_little_cool =	<11000 4150 3000 0 0
								11000 4480 2800 0 0
								11000 4480 2500 0 0
								11000 4480 2000 0 0
								11000 4520 1800 0 0
								11000 4520 1500 0 0
								11000 4530 1000 1 0>;
				strategy_temp_normal_low =	<11000 4520 3000 0 0
								11000 4520 2500 0 0
								11000 4520 2000 0 0
								11000 4520 1500 0 0
								11000 4530 1000 1 0>;
				strategy_temp_normal_high =	<11000 4520 3000 0 0
								11000 4520 2500 0 0
								11000 4520 2000 0 0
								11000 4520 1500 0 0
								11000 4530 1000 1 0>;
				strategy_temp_warm =		<11000 4120 1300 0 0
								11000 4130 1000 1 0>;
			};
			strategy_soc_range_mid_low {
				strategy_temp_little_cold =	<11000 4460 2000 0 0
								11000 4460 1800 0 0
								11000 4460 1500 0 0
								11000 4470 1000 1 0>;
				strategy_temp_cool =		<11000 4460 2500 0 0
								11000 4460 2000 0 0
								11000 4460 1800 0 0
								11000 4460 1500 0 0
								11000 4470 1000 1 0>;
				strategy_temp_little_cool =	<11000 4150 3000 0 0
								11000 4480 2800 0 0
								11000 4480 2500 0 0
								11000 4480 2000 0 0
								11000 4520 1800 0 0
								11000 4520 1500 0 0
								11000 4530 1000 1 0>;
				strategy_temp_normal_low =	<11000 4520 3000 0 0
								11000 4520 2500 0 0
								11000 4520 2000 0 0
								11000 4520 1500 0 0
								11000 4530 1000 1 0>;
				strategy_temp_normal_high =	<11000 4520 3000 0 0
								11000 4520 2500 0 0
								11000 4520 2000 0 0
								11000 4520 1500 0 0
								11000 4530 1000 1 0>;
				strategy_temp_warm =		<11000 4120 1300 0 0
								11000 4130 1000 1 0>;
			};
			strategy_soc_range_mid {
				strategy_temp_little_cold =	<11000 4460 1500 0 0
								11000 4470 1000 1 0>;
				strategy_temp_cool =		<11000 4460 1500 0 0
								11000 4470 1000 1 0>;
				strategy_temp_little_cool =	<11000 4480 2000 0 0
								11000 4520 1800 0 0
								11000 4520 1500 0 0
								11000 4530 1000 1 0>;
				strategy_temp_normal_low =	<11000 4520 2500 0 0
								11000 4520 2000 0 0
								11000 4520 1500 0 0
								11000 4530 1000 1 0>;
				strategy_temp_normal_high =	<11000 4520 3000 0 0
								11000 4520 2500 0 0
								11000 4520 2000 0 0
								11000 4520 1500 0 0
								11000 4530 1000 1 0>;
				strategy_temp_warm =		<11000 4130 1000 1 0>;
			};
			strategy_soc_range_mid_high {
				strategy_temp_little_cold =	<11000 4470 1000 1 0>;
				strategy_temp_cool =		<11000 4470 1000 1 0>;
				strategy_temp_little_cool =	<11000 4520 1500 0 0
								11000 4530 1000 1 0>;
				strategy_temp_normal_low =	<11000 4520 1500 0 0
								11000 4530 1000 1 0>;
				strategy_temp_normal_high =	<11000 4520 2000 0 0
								11000 4520 1500 0 0
								11000 4530 1000 1 0>;
				strategy_temp_warm =		<11000 4130 1000 1 0>;
			};
			strategy_soc_range_high {
				strategy_temp_little_cold =	<11000 4470 1000 1 0>;
				strategy_temp_cool =		<11000 4470 1000 1 0>;
				strategy_temp_little_cool =	<11000 4530 1000 1 0>;
				strategy_temp_normal_low =	<11000 4530 1000 1 0>;
				strategy_temp_normal_high =	<11000 4530 1000 1 0>;
				strategy_temp_warm =		<11000 4130 1000 1 0>;
			};
		};
		oplus,impedance_node {
			ufcs_input_impedance: ufcs_input_impedance {
				node_name = "ufcs_input";
				default_impedance_mohm = <270>;
				default_curr_ma = <3000>;
				current_drop_table = <
					30  3000
					70  3000
					80  2000
					100 1000
					150 0
				>;
			};
		};
	};
};
/* chagrge end */
